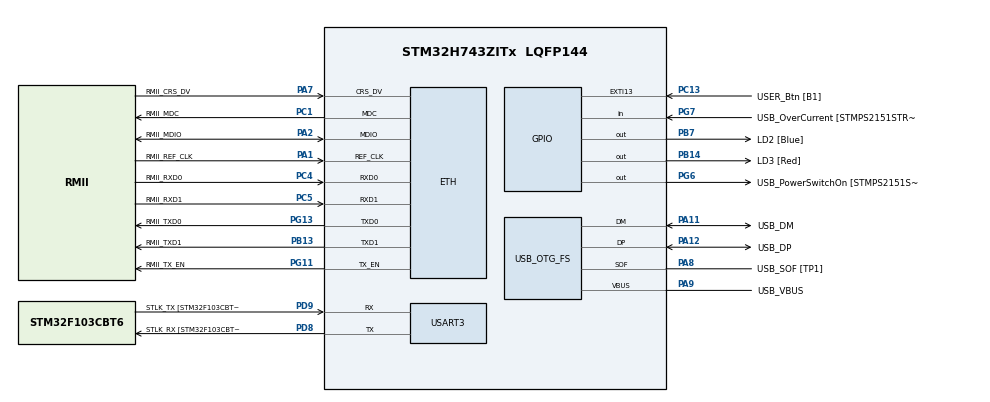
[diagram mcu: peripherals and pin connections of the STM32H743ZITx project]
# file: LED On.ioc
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ETH.MediaInterface=HAL_ETH_RMII_MODE
Mcu.Family=STM32H7
Mcu.Name=STM32H743ZITx
Mcu.Package=LQFP144
NVIC.PriorityGroup=NVIC_PRIORITYGROUP_4
PA1.GPIO_Label=RMII_REF_CLK
PA1.Mode=RMII
PA1.Signal=ETH_REF_CLK
PA10.GPIO_Label=USB_ID
PA10.Signal=USB_OTG_FS_ID
PA11.GPIO_Label=USB_DM
PA11.Mode=Device_Only
PA11.Signal=USB_OTG_FS_DM
PA12.GPIO_Label=USB_DP
PA12.Mode=Device_Only
PA12.Signal=USB_OTG_FS_DP
PA13\ (JTMS/SWDIO).GPIO_Label=TMS
PA13\ (JTMS/SWDIO).Mode=Serial_Wire
PA13\ (JTMS/SWDIO).Signal=SYS_JTMS-SWDIO
PA14\ (JTCK/SWCLK).GPIO_Label=TCK
PA14\ (JTCK/SWCLK).Mode=Serial_Wire
PA14\ (JTCK/SWCLK).Signal=SYS_JTCK-SWCLK
PA2.GPIO_Label=RMII_MDIO
PA2.Mode=RMII
PA2.Signal=ETH_MDIO
PA7.GPIO_Label=RMII_CRS_DV
PA7.Mode=RMII
PA7.Signal=ETH_CRS_DV
PA8.GPIO_Label=USB_SOF [TP1]
PA8.Mode=Activate_SOF_FS
PA8.Signal=USB_OTG_FS_SOF
PA9.GPIO_Label=USB_VBUS
PA9.Mode=Activate_VBUS
PA9.Signal=USB_OTG_FS_VBUS
PB13.GPIO_Label=RMII_TXD1
PB13.Mode=RMII
PB13.Signal=ETH_TXD1
PB14.GPIO_Label=LD3 [Red]
PB14.Signal=GPIO_Output
PB3\ (JTDO/TRACESWO).GPIO_Label=SWO
PB3\ (JTDO/TRACESWO).Signal=SYS_JTDO-SWO
PB7.GPIO_Label=LD2 [Blue]
PB7.Signal=GPIO_Output
PC1.GPIO_Label=RMII_MDC
PC1.Mode=RMII
PC1.Signal=ETH_MDC
PC13.GPIO_Label=USER_Btn [B1]
PC13.Signal=GPXTI13
PC14-OSC32_IN\ (OSC32_IN).Mode=LSE-External-Oscillator
PC14-OSC32_IN\ (OSC32_IN).Signal=RCC_OSC32_IN
PC15-OSC32_OUT\ (OSC32_OUT).Mode=LSE-External-Oscillator
PC15-OSC32_OUT\ (OSC32_OUT).Signal=RCC_OSC32_OUT
PC4.GPIO_Label=RMII_RXD0
PC4.Mode=RMII
PC4.Signal=ETH_RXD0
PC5.GPIO_Label=RMII_RXD1
PC5.Mode=RMII
PC5.Signal=ETH_RXD1
PD8.GPIO_Label=STLK_RX [STM32F103CBT6_PA3]
PD8.Mode=Asynchronous
PD8.Signal=USART3_TX
PD9.GPIO_Label=STLK_TX [STM32F103CBT6_PA2]
PD9.Mode=Asynchronous
PD9.Signal=USART3_RX
PG11.GPIO_Label=RMII_TX_EN
PG11.Mode=RMII
PG11.Signal=ETH_TX_EN
PG13.GPIO_Label=RMII_TXD0
PG13.Mode=RMII
PG13.Signal=ETH_TXD0
PG6.GPIO_Label=USB_PowerSwitchOn [STMPS2151STR_EN]
PG6.Signal=GPIO_Output
PG7.GPIO_Label=USB_OverCurrent [STMPS2151STR_FAULT]
PG7.Signal=GPIO_Input
PH0-OSC_IN\ (PH0).GPIO_Label=MCO
PH0-OSC_IN\ (PH0).Mode=HSE-External-Clock-Source
PH0-OSC_IN\ (PH0).Signal=RCC_OSC_IN
PH1-OSC_OUT\ (PH1).Mode=HSE-External-Clock-Source
PH1-OSC_OUT\ (PH1).Signal=RCC_OSC_OUT
ProjectManager.HeapSize=0x200
ProjectManager.StackSize=0x400
ProjectManager.TargetToolchain=TrueSTUDIO
RCC.48MHZClocksFreq_Value=24000000
RCC.ADCFreq_Value=16125000
RCC.AHBFreq_Value=216000000
RCC.APB1CLKDivider=RCC_HCLK_DIV4
RCC.APB1Freq_Value=96000000
RCC.APB1TimFreq_Value=108000000
RCC.APB2CLKDivider=RCC_HCLK_DIV2
RCC.APB2Freq_Value=96000000
RCC.APB2TimFreq_Value=216000000
RCC.APB3Freq_Value=96000000
RCC.APB4Freq_Value=96000000
RCC.CortexFreq_Value=96000000
RCC.DIVM1=1
RCC.DIVN1=24
RCC.DIVQ1=4
RCC.HCLKFreq_Value=96000000
RCC.HSE_VALUE=8000000
RCC.HSI_VALUE=64000000
RCC.PLLM=25
RCC.PLLMUL=RCC_PLL_MUL9
RCC.PLLN=432
RCC.PLLQ=9
RCC.PRESCALERUSB=RCC_USBCLKSOURCE_PLL_DIV1_5
RCC.SYSCLKFreq_VALUE=96000000
RCC.SYSCLKSource=RCC_SYSCLKSOURCE_PLLCLK
RCC.SYSCLKSourceVirtual=RCC_SYSCLKSOURCE_PLLCLK
RCC.USBFreq_Value=48000000
RCC.VCOOutputFreq_Value=432000000
USART3.VirtualMode-Asynchronous=VM_ASYNC
USB_OTG_FS.VirtualMode=Device_Only
board=NUCLEO-H743ZI

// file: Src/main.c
/* USER CODE BEGIN Header */
/**
  ******************************************************************************
  * @file           : main.c
  * @brief          : Main program body
  ******************************************************************************
  ** This notice applies to any and all portions of this file
  * that are not between comment pairs USER CODE BEGIN and
  * USER CODE END. Other portions of this file, whether
  * inserted by the user or by software development tools
  * are owned by their respective copyright owners.
  *
  * COPYRIGHT(c) 2018 STMicroelectronics
  *
  * Redistribution and use in source and binary forms, with or without modification,
  * are permitted provided that the following conditions are met:
  *   1. Redistributions of source code must retain the above copyright notice,
  *      this list of conditions and the following disclaimer.
  *   2. Redistributions in binary form must reproduce the above copyright notice,
  *      this list of conditions and the following disclaimer in the documentation
  *      and/or other materials provided with the distribution.
  *   3. Neither the name of STMicroelectronics nor the names of its contributors
  *      may be used to endorse or promote products derived from this software
  *      without specific prior written permission.
  *
  * THIS SOFTWARE IS PROVIDED BY THE COPYRIGHT HOLDERS AND CONTRIBUTORS "AS IS"
  * AND ANY EXPRESS OR IMPLIED WARRANTIES, INCLUDING, BUT NOT LIMITED TO, THE
  * IMPLIED WARRANTIES OF MERCHANTABILITY AND FITNESS FOR A PARTICULAR PURPOSE ARE
  * DISCLAIMED. IN NO EVENT SHALL THE COPYRIGHT HOLDER OR CONTRIBUTORS BE LIABLE
  * FOR ANY DIRECT, INDIRECT, INCIDENTAL, SPECIAL, EXEMPLARY, OR CONSEQUENTIAL
  * DAMAGES (INCLUDING, BUT NOT LIMITED TO, PROCUREMENT OF SUBSTITUTE GOODS OR
  * SERVICES; LOSS OF USE, DATA, OR PROFITS; OR BUSINESS INTERRUPTION) HOWEVER
  * CAUSED AND ON ANY THEORY OF LIABILITY, WHETHER IN CONTRACT, STRICT LIABILITY,
  * OR TORT (INCLUDING NEGLIGENCE OR OTHERWISE) ARISING IN ANY WAY OUT OF THE USE
  * OF THIS SOFTWARE, EVEN IF ADVISED OF THE POSSIBILITY OF SUCH DAMAGE.
  *
  ******************************************************************************
  */
/* USER CODE END Header */

#include "main.h"
#include "string.h"

#if defined ( __ICCARM__ ) /*!< IAR Compiler */

#pragma location=0x30040000
ETH_DMADescTypeDef  DMARxDscrTab[ETH_RX_DESC_CNT]; /* Ethernet Rx DMA Descriptors */
#pragma location=0x30040060
ETH_DMADescTypeDef  DMATxDscrTab[ETH_TX_DESC_CNT]; /* Ethernet Tx DMA Descriptors */
#pragma location=0x30040200
uint8_t Rx_Buff[ETH_RX_DESC_CNT][ETH_MAX_PACKET_SIZE]; /* Ethernet Receive Buffers */

#elif defined ( __CC_ARM )  /* MDK ARM Compiler */

__attribute__((at(0x30040000))) ETH_DMADescTypeDef  DMARxDscrTab[ETH_RX_DESC_CNT]; /* Ethernet Rx DMA Descriptors */
__attribute__((at(0x30040060))) ETH_DMADescTypeDef  DMATxDscrTab[ETH_TX_DESC_CNT]; /* Ethernet Tx DMA Descriptors */
__attribute__((at(0x30040200))) uint8_t Rx_Buff[ETH_RX_DESC_CNT][ETH_MAX_PACKET_SIZE]; /* Ethernet Receive Buffer */

#elif defined ( __GNUC__ ) /* GNU Compiler */

ETH_DMADescTypeDef DMARxDscrTab[ETH_RX_DESC_CNT] __attribute__((section(".RxDecripSection"))); /* Ethernet Rx DMA Descriptors */
ETH_DMADescTypeDef DMATxDscrTab[ETH_TX_DESC_CNT] __attribute__((section(".TxDecripSection")));   /* Ethernet Tx DMA Descriptors */
uint8_t Rx_Buff[ETH_RX_DESC_CNT][ETH_MAX_PACKET_SIZE] __attribute__((section(".RxArraySection"))); /* Ethernet Receive Buffers */

#endif

ETH_TxPacketConfig TxConfig;

ETH_HandleTypeDef heth;

UART_HandleTypeDef huart3;

PCD_HandleTypeDef hpcd_USB_OTG_FS;

void SystemClock_Config(void);
static void MX_GPIO_Init(void);
static void MX_ETH_Init(void);
static void MX_USART3_UART_Init(void);
static void MX_USB_OTG_FS_PCD_Init(void);

int main(void)
{

  /* MCU Configuration--------------------------------------------------------*/

  /* Reset of all peripherals, Initializes the Flash interface and the Systick. */
  HAL_Init();

  /* Configure the system clock */
  SystemClock_Config();

  /* Initialize all configured peripherals */
  MX_GPIO_Init();
  MX_ETH_Init();
  MX_USART3_UART_Init();
  MX_USB_OTG_FS_PCD_Init();
  /* USER CODE BEGIN 2 */
  bool flag = false;
  /* USER CODE END 2 */

  /* Infinite loop */
  while (1)
  {
	  HAL_GPIO_WritePin(GPIOB, LD3_Pin|LD2_Pin, GPIO_PIN_RESET);
	  HAL_Delay(500);
	  if(HAL_GPIO_ReadPin(USER_Btn_GPIO_Port, USER_Btn_Pin) == GPIO_PIN_SET)
	  {
		  if(flag)
			  flag = false;
		  else
			  flag = true;
		  if(flag == true)
		  {
			  HAL_GPIO_TogglePin(GPIOB, LD2_Pin);
		  }
		  else if(flag == false)
		  {
			  HAL_GPIO_TogglePin(GPIOB, LD3_Pin);
		  }

		HAL_Delay(200);
	  }
//else

  }
}

void SystemClock_Config(void)
{
  RCC_OscInitTypeDef RCC_OscInitStruct = {0};
  RCC_ClkInitTypeDef RCC_ClkInitStruct = {0};
  RCC_PeriphCLKInitTypeDef PeriphClkInitStruct = {0};

  /**Supply configuration update enable
  */
  MODIFY_REG(PWR->CR3, PWR_CR3_SCUEN, 0);
  /**Configure the main internal regulator output voltage
  */
  __HAL_PWR_VOLTAGESCALING_CONFIG(PWR_REGULATOR_VOLTAGE_SCALE3);

  while ((PWR->D3CR & (PWR_D3CR_VOSRDY)) != PWR_D3CR_VOSRDY)
  {

  }
  /**Initializes the CPU, AHB and APB busses clocks
  */
  RCC_OscInitStruct.OscillatorType = RCC_OSCILLATORTYPE_HSE;
  RCC_OscInitStruct.HSEState = RCC_HSE_BYPASS;
  RCC_OscInitStruct.PLL.PLLState = RCC_PLL_ON;
  RCC_OscInitStruct.PLL.PLLSource = RCC_PLLSOURCE_HSE;
  RCC_OscInitStruct.PLL.PLLM = 1;
  RCC_OscInitStruct.PLL.PLLN = 24;
  RCC_OscInitStruct.PLL.PLLP = 2;
  RCC_OscInitStruct.PLL.PLLQ = 4;
  RCC_OscInitStruct.PLL.PLLR = 2;
  RCC_OscInitStruct.PLL.PLLRGE = RCC_PLL1VCIRANGE_3;
  RCC_OscInitStruct.PLL.PLLVCOSEL = RCC_PLL1VCOWIDE;
  RCC_OscInitStruct.PLL.PLLFRACN = 0;
  if (HAL_RCC_OscConfig(&RCC_OscInitStruct) != HAL_OK)
  {
    Error_Handler();
  }
  /**Initializes the CPU, AHB and APB busses clocks
  */
  RCC_ClkInitStruct.ClockType = RCC_CLOCKTYPE_HCLK|RCC_CLOCKTYPE_SYSCLK
                              |RCC_CLOCKTYPE_PCLK1|RCC_CLOCKTYPE_PCLK2
                              |RCC_CLOCKTYPE_D3PCLK1|RCC_CLOCKTYPE_D1PCLK1;
  RCC_ClkInitStruct.SYSCLKSource = RCC_SYSCLKSOURCE_PLLCLK;
  RCC_ClkInitStruct.SYSCLKDivider = RCC_SYSCLK_DIV1;
  RCC_ClkInitStruct.AHBCLKDivider = RCC_HCLK_DIV1;
  RCC_ClkInitStruct.APB3CLKDivider = RCC_APB3_DIV1;
  RCC_ClkInitStruct.APB1CLKDivider = RCC_APB1_DIV1;
  RCC_ClkInitStruct.APB2CLKDivider = RCC_APB2_DIV1;
  RCC_ClkInitStruct.APB4CLKDivider = RCC_APB4_DIV1;

  if (HAL_RCC_ClockConfig(&RCC_ClkInitStruct, FLASH_LATENCY_1) != HAL_OK)
  {
    Error_Handler();
  }
  PeriphClkInitStruct.PeriphClockSelection = RCC_PERIPHCLK_USART3|RCC_PERIPHCLK_USB;
  PeriphClkInitStruct.Usart234578ClockSelection = RCC_USART234578CLKSOURCE_D2PCLK1;
  PeriphClkInitStruct.UsbClockSelection = RCC_USBCLKSOURCE_PLL;
  if (HAL_RCCEx_PeriphCLKConfig(&PeriphClkInitStruct) != HAL_OK)
  {
    Error_Handler();
  }
}

static void MX_ETH_Init(void)
{

   uint8_t MACAddr[6] ;

  heth.Instance = ETH;
  MACAddr[0] = 0x00;
  MACAddr[1] = 0x80;
  MACAddr[2] = 0xE1;
  MACAddr[3] = 0x00;
  MACAddr[4] = 0x00;
  MACAddr[5] = 0x00;
  heth.Init.MACAddr = &MACAddr[0];
  heth.Init.MediaInterface = HAL_ETH_RMII_MODE;
  heth.Init.TxDesc = DMATxDscrTab;
  heth.Init.RxDesc = DMARxDscrTab;
  heth.Init.RxBuffLen = 1524;

  if (HAL_ETH_Init(&heth) != HAL_OK)
  {
    Error_Handler();
  }

  memset(&TxConfig, 0 , sizeof(ETH_TxPacketConfig));
  TxConfig.Attributes = ETH_TX_PACKETS_FEATURES_CSUM | ETH_TX_PACKETS_FEATURES_CRCPAD;
  TxConfig.ChecksumCtrl = ETH_CHECKSUM_IPHDR_PAYLOAD_INSERT_PHDR_CALC;
  TxConfig.CRCPadCtrl = ETH_CRC_PAD_INSERT;

}

static void MX_USART3_UART_Init(void)
{

  huart3.Instance = USART3;
  huart3.Init.BaudRate = 115200;
  huart3.Init.WordLength = UART_WORDLENGTH_8B;
  huart3.Init.StopBits = UART_STOPBITS_1;
  huart3.Init.Parity = UART_PARITY_NONE;
  huart3.Init.Mode = UART_MODE_TX_RX;
  huart3.Init.HwFlowCtl = UART_HWCONTROL_NONE;
  huart3.Init.OverSampling = UART_OVERSAMPLING_16;
  huart3.Init.OneBitSampling = UART_ONE_BIT_SAMPLE_DISABLE;
  huart3.Init.Prescaler = UART_PRESCALER_DIV1;
  huart3.Init.FIFOMode = UART_FIFOMODE_DISABLE;
  huart3.Init.TXFIFOThreshold = UART_TXFIFO_THRESHOLD_1_8;
  huart3.Init.RXFIFOThreshold = UART_RXFIFO_THRESHOLD_1_8;
  huart3.AdvancedInit.AdvFeatureInit = UART_ADVFEATURE_NO_INIT;
  if (HAL_UART_Init(&huart3) != HAL_OK)
  {
    Error_Handler();
  }

}

static void MX_USB_OTG_FS_PCD_Init(void)
{

  hpcd_USB_OTG_FS.Instance = USB_OTG_FS;
  hpcd_USB_OTG_FS.Init.dev_endpoints = 9;
  hpcd_USB_OTG_FS.Init.speed = PCD_SPEED_FULL;
  hpcd_USB_OTG_FS.Init.dma_enable = DISABLE;
  hpcd_USB_OTG_FS.Init.ep0_mps = DEP0CTL_MPS_64;
  hpcd_USB_OTG_FS.Init.phy_itface = PCD_PHY_EMBEDDED;
  hpcd_USB_OTG_FS.Init.Sof_enable = ENABLE;
  hpcd_USB_OTG_FS.Init.low_power_enable = DISABLE;
  hpcd_USB_OTG_FS.Init.lpm_enable = DISABLE;
  hpcd_USB_OTG_FS.Init.battery_charging_enable = ENABLE;
  hpcd_USB_OTG_FS.Init.vbus_sensing_enable = ENABLE;
  hpcd_USB_OTG_FS.Init.use_dedicated_ep1 = DISABLE;
  if (HAL_PCD_Init(&hpcd_USB_OTG_FS) != HAL_OK)
  {
    Error_Handler();
  }

}

static void MX_GPIO_Init(void)
{
  GPIO_InitTypeDef GPIO_InitStruct = {0};

  /* GPIO Ports Clock Enable */
  __HAL_RCC_GPIOC_CLK_ENABLE();
  __HAL_RCC_GPIOH_CLK_ENABLE();
  __HAL_RCC_GPIOA_CLK_ENABLE();
  __HAL_RCC_GPIOB_CLK_ENABLE();
  __HAL_RCC_GPIOD_CLK_ENABLE();
  __HAL_RCC_GPIOG_CLK_ENABLE();

  /*Configure GPIO pin Output Level */
  HAL_GPIO_WritePin(GPIOB, LD3_Pin|LD2_Pin, GPIO_PIN_RESET);

  /*Configure GPIO pin Output Level */
  HAL_GPIO_WritePin(USB_PowerSwitchOn_GPIO_Port, USB_PowerSwitchOn_Pin, GPIO_PIN_RESET);

  /*Configure GPIO pin : USER_Btn_Pin */
  GPIO_InitStruct.Pin = USER_Btn_Pin;
  GPIO_InitStruct.Mode = GPIO_MODE_IT_RISING;
  GPIO_InitStruct.Pull = GPIO_PULLDOWN;
  HAL_GPIO_Init(USER_Btn_GPIO_Port, &GPIO_InitStruct);

  /*Configure GPIO pins : LD3_Pin LD2_Pin */
  GPIO_InitStruct.Pin = LD3_Pin|LD2_Pin;
  GPIO_InitStruct.Mode = GPIO_MODE_OUTPUT_PP;
  GPIO_InitStruct.Pull = GPIO_NOPULL;
  GPIO_InitStruct.Speed = GPIO_SPEED_FREQ_LOW;
  HAL_GPIO_Init(GPIOB, &GPIO_InitStruct);

  /*Configure GPIO pin : USB_PowerSwitchOn_Pin */
  GPIO_InitStruct.Pin = USB_PowerSwitchOn_Pin;
  GPIO_InitStruct.Mode = GPIO_MODE_OUTPUT_PP;
  GPIO_InitStruct.Pull = GPIO_NOPULL;
  GPIO_InitStruct.Speed = GPIO_SPEED_FREQ_LOW;
  HAL_GPIO_Init(USB_PowerSwitchOn_GPIO_Port, &GPIO_InitStruct);

  /*Configure GPIO pin : USB_OverCurrent_Pin */
  GPIO_InitStruct.Pin = USB_OverCurrent_Pin;
  GPIO_InitStruct.Mode = GPIO_MODE_INPUT;
  GPIO_InitStruct.Pull = GPIO_NOPULL;
  HAL_GPIO_Init(USB_OverCurrent_GPIO_Port, &GPIO_InitStruct);

}

void Error_Handler(void)
{
}

/************************ (C) COPYRIGHT STMicroelectronics *****END OF FILE****/
